# ESP32-S31 register map
Vendor: ESPRESSIF SYSTEMS (SHANGHAI) CO., LTD.; Series: ESP32 S-Series; File version: 1
CPU: RV32IMAFC r0p0, little endian, no MPU, FPU, 0 interrupt priority bits
Address unit: 32 bits
Registers are 32-bit, read-write, reset 0x0 unless marked. A register's access mark holds for its fields unless they carry their own. Offsets are from the block's base; [hi:lo] are bit positions; {n}, {i} and the like mark numbered series.

## HP_SYS — High-Power System
Base 0x20586000
0x00 VER_DATE reset 0x20250402
  [31:0] HP_REG_VER_DATE
0x04 HP_CLK_EN
  [0] HP_REG_CLK_EN
{0x10+4i} HP_CPU_INT_FROM_CPU_{i} (i=0..3)
  [0] HP_CPU_INT_FROM_CPU_{i} — set 1 will triger a interrupt
0x28 HP_MODEM_DIAG_EN
  [31:0] HP_REG_MODEM_DIAG_EN — set reg_modem_diag_en[15:0] will let hp_probe_out[15:0] used as modem_diag[15:0], set reg_modem_diag_en[31:16] will let lcd_data_out[15:0] used as modem_diag[31:16]
0x3C HP_TCM_RAM_PWR_CTRL0
  [0] HP_REG_HP_TCM_CLK_FORCE_ON — hp_tcm clk gatig force on
0x40 HP_ROM_PWR_CTRL0
  [0] HP_REG_HP_ROM_CLK_FORCE_ON — hp_rom clk gating force on
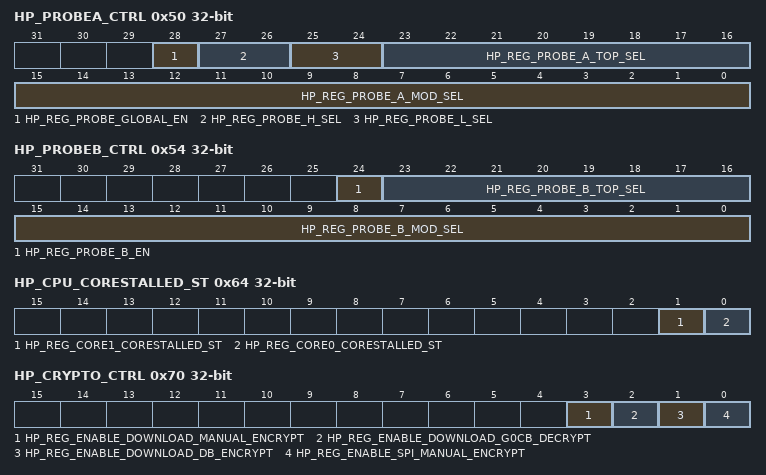
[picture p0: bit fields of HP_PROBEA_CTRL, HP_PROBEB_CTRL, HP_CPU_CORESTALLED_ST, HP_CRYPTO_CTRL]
0x50 HP_PROBEA_CTRL
  [28] HP_REG_PROBE_GLOBAL_EN — Set this bit to enable global debug probe in hp system.
  [27:26] HP_REG_PROBE_H_SEL — Tihs field is used to selec probe_out[31:16]
  [25:24] HP_REG_PROBE_L_SEL — Tihs field is used to selec probe_out[31:16]
  [23:16] HP_REG_PROBE_A_TOP_SEL — Tihs field is used to selec module's probe_out[31:0] as probe out in a mode
  [15:0] HP_REG_PROBE_A_MOD_SEL — Tihs field is used to selec probe_group from probe_group0 to probe_group15 for module's probe_out[31:0] in a mode
0x54 HP_PROBEB_CTRL
  [24] HP_REG_PROBE_B_EN — Set this bit to enable b mode for debug probe. 1: b mode, 0: a mode.
  [23:16] HP_REG_PROBE_B_TOP_SEL — Tihs field is used to select module's probe_out[31:0] as probe_out in b mode
  [15:0] HP_REG_PROBE_B_MOD_SEL — Tihs field is used to selec probe_group from probe_group0 to probe_group15 for module's probe_out[31:0] in b mode.
0x5C HP_PROBE_OUT ro
  [31:0] HP_REG_PROBE_TOP_OUT
0x64 HP_CPU_CORESTALLED_ST ro
  [1] HP_REG_CORE1_CORESTALLED_ST — hp core1 corestalled status
  [0] HP_REG_CORE0_CORESTALLED_ST — hp core0 corestalled status
0x70 HP_CRYPTO_CTRL
  [3] HP_REG_ENABLE_DOWNLOAD_MANUAL_ENCRYPT, [2] HP_REG_ENABLE_DOWNLOAD_G0CB_DECRYPT, [1] HP_REG_ENABLE_DOWNLOAD_DB_ENCRYPT, [0] HP_REG_ENABLE_SPI_MANUAL_ENCRYPT
0x7C HP_IOMUX_FPGA_DEBUG reset 0x1
  [0] HP_REG_FPGA_DEBUG — iomux fpga debug
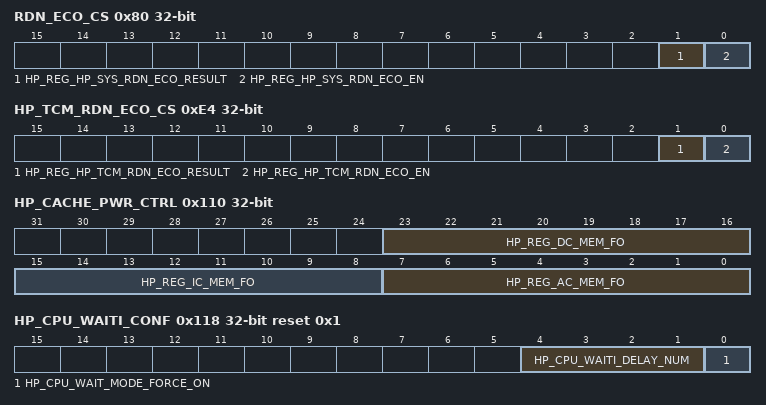
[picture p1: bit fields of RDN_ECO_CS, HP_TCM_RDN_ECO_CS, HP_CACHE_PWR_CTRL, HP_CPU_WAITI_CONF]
0x80 RDN_ECO_CS access per field
  [1] HP_REG_HP_SYS_RDN_ECO_RESULT ro, [0] HP_REG_HP_SYS_RDN_ECO_EN rw
0xE4 HP_TCM_RDN_ECO_CS access per field
  [1] HP_REG_HP_TCM_RDN_ECO_RESULT ro, [0] HP_REG_HP_TCM_RDN_ECO_EN rw
0xE8 HP_TCM_RDN_ECO_LOW
  [31:0] HP_REG_HP_TCM_RDN_ECO_LOW
0xEC HP_TCM_RDN_ECO_HIGH reset 0xFFFFFFFF
  [31:0] HP_REG_HP_TCM_RDN_ECO_HIGH
0x110 HP_CACHE_PWR_CTRL
  [23:16] HP_REG_DC_MEM_FO — need_des
  [15:8] HP_REG_IC_MEM_FO — need_des
  [7:0] HP_REG_AC_MEM_FO — need_des
0x114 HP_TCM_DATA_DUMP_CTRL — need_des
  [31:0] HP_TCM_DATA_DUMP_EN — hp tcm_data dump switch
0x118 HP_CPU_WAITI_CONF reset 0x1 — CPU_WAITI configuration register
  [4:1] HP_CPU_WAITI_DELAY_NUM — This field used to set delay cycle when cpu enter waiti mode, after delay waiti_clk will close
  [0] HP_CPU_WAIT_MODE_FORCE_ON — Set 1 to force cpu_waiti_clk enable.
0x11C CORE_DEBUG_RUNSTALL_CONF — Core Debug runstall configure register
  [0] CORE_DEBUG_RUNSTALL_ENABLE — Set this field to 1 to enable debug runstall feature between HP-core and LP-core.
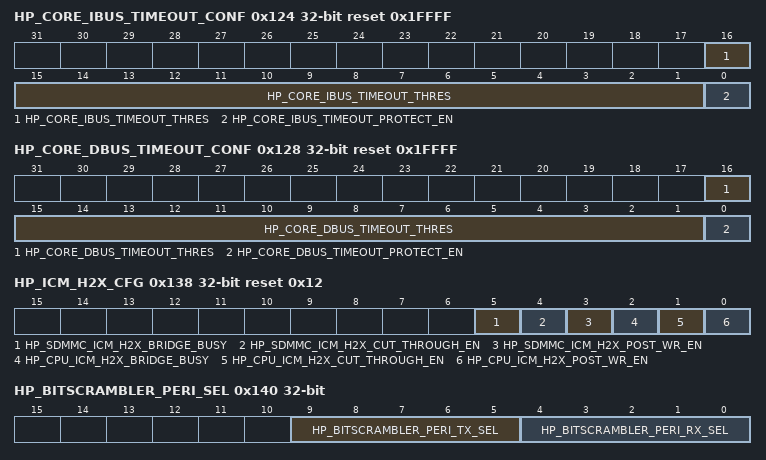
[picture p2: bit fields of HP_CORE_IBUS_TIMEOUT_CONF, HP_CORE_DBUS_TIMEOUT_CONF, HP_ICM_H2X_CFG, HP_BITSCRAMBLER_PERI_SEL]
0x124 HP_CORE_IBUS_TIMEOUT_CONF reset 0x1FFFF — need_des
  [16:1] HP_CORE_IBUS_TIMEOUT_THRES — This field used to set hp core0&1 ibus timeout threshold
  [0] HP_CORE_IBUS_TIMEOUT_PROTECT_EN — set this field to 1 to enable hp core0&1 ibus timeout handle
0x128 HP_CORE_DBUS_TIMEOUT_CONF reset 0x1FFFF — need_des
  [16:1] HP_CORE_DBUS_TIMEOUT_THRES — This field used to set hp core0&1 dbus timeout threshold
  [0] HP_CORE_DBUS_TIMEOUT_PROTECT_EN — set this field to 1 to enable hp core0&1 dbus timeout handle
0x138 HP_ICM_H2X_CFG access per field reset 0x12 — need_des
  [5] HP_SDMMC_ICM_H2X_BRIDGE_BUSY ro — need_des
  [4] HP_SDMMC_ICM_H2X_CUT_THROUGH_EN rw — need_des
  [3] HP_SDMMC_ICM_H2X_POST_WR_EN rw — need_des
  [2] HP_CPU_ICM_H2X_BRIDGE_BUSY ro — need_des
  [1] HP_CPU_ICM_H2X_CUT_THROUGH_EN rw — need_des
  [0] HP_CPU_ICM_H2X_POST_WR_EN rw — need_des
0x140 HP_BITSCRAMBLER_PERI_SEL — Bitscrambler Peri Sel
  [9:5] HP_BITSCRAMBLER_PERI_TX_SEL — Set this field to sel peri with DMA TX interface to connec with bitscrambler: lcd_cam: 5'h1, gpspi2: 5'h2: gpspi3: 5'h3, parl_io:5'h4, aes: 5'h5, sha: 5'h6, adc: 5'h7, i2s0_ch0: 5'h8, i2s0_ch1: 5'h9, i2s0_ch2: 5'ha, i2s0_ch3: 5'hb, i2s1_ch0: 5'hc, i2s1_ch1: 5'hd, i2s1_ch2: 5'he, i2s1_ch3: 5'hf, uhci0: 5'h10, RMT: 5'h11, none: else.
  [4:0] HP_BITSCRAMBLER_PERI_RX_SEL — Set this field to sel peri with DMA RX interface to connec with bitscrambler: lcd_cam: 5'h1, gpspi2: 5'h2: gpspi3: 5'h3, parl_io:5'h4, aes: 5'h5, sha: 5'h6, adc: 5'h7, i2s0_ch0: 5'h8, i2s0_ch1: 5'h9, i2s0_ch2: 5'ha, i2s0_ch3: 5'hb, i2s1_ch0: 5'hc, i2s1_ch1: 5'hd, i2s1_ch2: 5'he, i2s1_ch3: 5'hf, uhci0: 5'h10, RMT: 5'h11, none: else.
0x148 GDMA_CTRL
  [1:0] DEBUG_CH_NUM
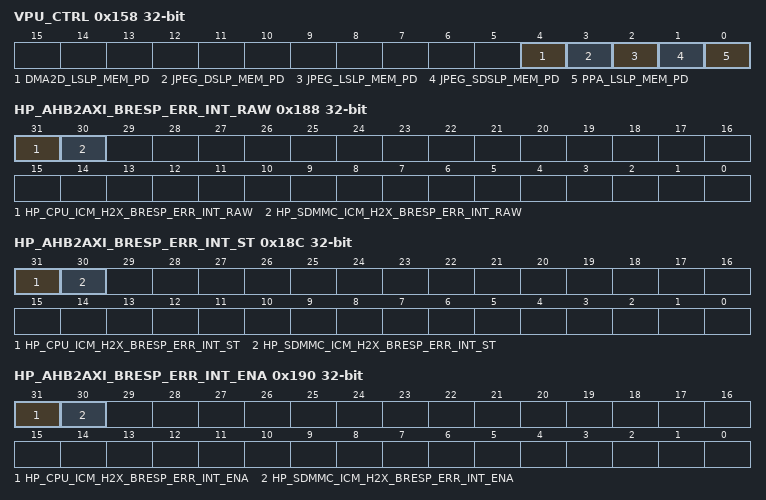
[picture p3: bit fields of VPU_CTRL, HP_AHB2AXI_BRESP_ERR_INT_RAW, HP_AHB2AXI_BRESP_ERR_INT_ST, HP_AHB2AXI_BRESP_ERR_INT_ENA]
0x158 VPU_CTRL
  [4] DMA2D_LSLP_MEM_PD, [3] JPEG_DSLP_MEM_PD, [2] JPEG_LSLP_MEM_PD, [1] JPEG_SDSLP_MEM_PD, [0] PPA_LSLP_MEM_PD
0x170 HP_DESIGN_FOR_VERIFICATION0 — need_des
  [31:0] HP_DFV0 — register for DV
0x174 HP_DESIGN_FOR_VERIFICATION1 — need_des
  [31:0] HP_DFV1 — register for DV
0x188 HP_AHB2AXI_BRESP_ERR_INT_RAW
  [31] HP_CPU_ICM_H2X_BRESP_ERR_INT_RAW — the raw interrupt status of bresp error, triggered when if bresp err occurs in post write mode in ahb2axi.
  [30] HP_SDMMC_ICM_H2X_BRESP_ERR_INT_RAW — the raw interrupt status of bresp error, triggered when if bresp err occurs in post write mode in ahb2axi.
0x18C HP_AHB2AXI_BRESP_ERR_INT_ST ro — need_des
  [31] HP_CPU_ICM_H2X_BRESP_ERR_INT_ST — the masked interrupt status of cpu_icm_h2x_bresp_err
  [30] HP_SDMMC_ICM_H2X_BRESP_ERR_INT_ST — the masked interrupt status of sdmmc_icm_h2x_bresp_err
0x190 HP_AHB2AXI_BRESP_ERR_INT_ENA — need_des
  [31] HP_CPU_ICM_H2X_BRESP_ERR_INT_ENA — Write 1 to enable cpu_icm_h2x_bresp_err int
  [30] HP_SDMMC_ICM_H2X_BRESP_ERR_INT_ENA — Write 1 to enable sdmmc_icm_h2x_bresp_err int
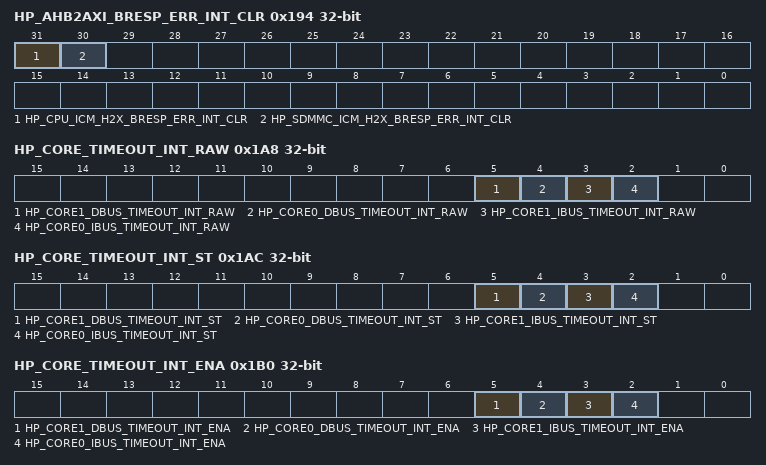
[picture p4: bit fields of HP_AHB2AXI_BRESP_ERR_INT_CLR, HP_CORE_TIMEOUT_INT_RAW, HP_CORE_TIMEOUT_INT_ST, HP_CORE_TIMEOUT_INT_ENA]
0x194 HP_AHB2AXI_BRESP_ERR_INT_CLR wo — need_des
  [31] HP_CPU_ICM_H2X_BRESP_ERR_INT_CLR — Write 1 to clear cpu_icm_h2x_bresp_err int
  [30] HP_SDMMC_ICM_H2X_BRESP_ERR_INT_CLR — Write 1 to clear sdmmc_icm_h2x_bresp_err int
0x1A0 HP_CORE_DMACTIVE_LPCORE ro — need_des
  [0] HP_CORE_DMACTIVE_LPCORE — hp core dmactive_lpcore value
0x1A4 HP_CORE_ERR_RESP_DIS — need_des
  [2:0] HP_CORE_ERR_RESP_DIS — Set bit0 to disable ibus err resp. Set bit1 to disable dbus err resp. Set bit 2 to disable ahb err resp.
0x1A8 HP_CORE_TIMEOUT_INT_RAW — Hp core bus timeout interrupt raw register
  [5] HP_CORE1_DBUS_TIMEOUT_INT_RAW — the raw interrupt status of hp core1 dbus timeout
  [4] HP_CORE0_DBUS_TIMEOUT_INT_RAW — the raw interrupt status of hp core0 dbus timeout
  [3] HP_CORE1_IBUS_TIMEOUT_INT_RAW — the raw interrupt status of hp core1 ibus timeout
  [2] HP_CORE0_IBUS_TIMEOUT_INT_RAW — the raw interrupt status of hp core0 ibus timeout
0x1AC HP_CORE_TIMEOUT_INT_ST ro — masked interrupt register
  [5] HP_CORE1_DBUS_TIMEOUT_INT_ST — the masked interrupt status of hp core1 dbus timeout
  [4] HP_CORE0_DBUS_TIMEOUT_INT_ST — the masked interrupt status of hp core0 dbus timeout
  [3] HP_CORE1_IBUS_TIMEOUT_INT_ST — the masked interrupt status of hp core1 ibus timeout
  [2] HP_CORE0_IBUS_TIMEOUT_INT_ST — the masked interrupt status of hp core0 ibus timeout
0x1B0 HP_CORE_TIMEOUT_INT_ENA — masked interrupt register
  [5] HP_CORE1_DBUS_TIMEOUT_INT_ENA — Write 1 to enable hp_core1_dbus_timeout int
  [4] HP_CORE0_DBUS_TIMEOUT_INT_ENA — Write 1 to enable hp_core0_dbus_timeout int
  [3] HP_CORE1_IBUS_TIMEOUT_INT_ENA — Write 1 to enable hp_core1_ibus_timeout int
  [2] HP_CORE0_IBUS_TIMEOUT_INT_ENA — Write 1 to enable hp_core0_ibus_timeout int
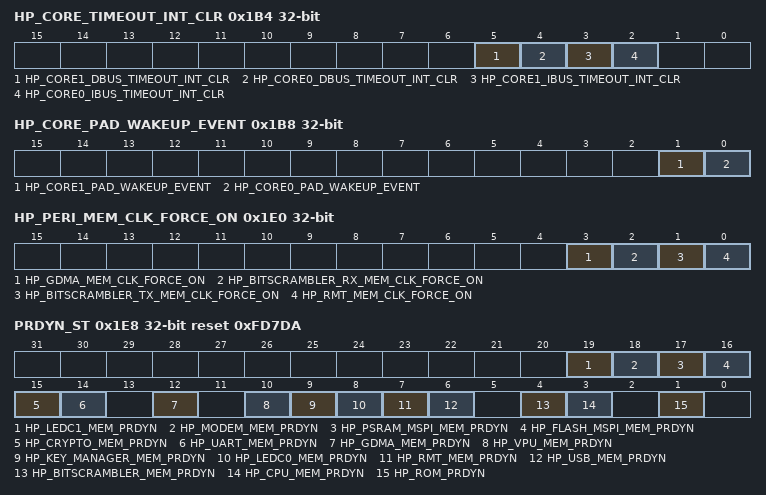
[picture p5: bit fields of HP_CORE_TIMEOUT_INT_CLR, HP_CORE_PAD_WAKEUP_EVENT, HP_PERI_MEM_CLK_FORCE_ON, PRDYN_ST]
0x1B4 HP_CORE_TIMEOUT_INT_CLR wo — interrupt clear register
  [5] HP_CORE1_DBUS_TIMEOUT_INT_CLR — Write 1 to clear hp_core1_dbus_timeout int
  [4] HP_CORE0_DBUS_TIMEOUT_INT_CLR — Write 1 to clear hp_core0_dbus_timeout int
  [3] HP_CORE1_IBUS_TIMEOUT_INT_CLR — Write 1 to clear hp_core1_ibus_timeout int
  [2] HP_CORE0_IBUS_TIMEOUT_INT_CLR — Write 1 to clear hp_core0_ibus_timeout int
0x1B8 HP_CORE_PAD_WAKEUP_EVENT — pad wakeup event register
  [1] HP_CORE1_PAD_WAKEUP_EVENT — wakeup core1 register
  [0] HP_CORE0_PAD_WAKEUP_EVENT — wakeup core0 register
0x1C0 HP_TWAI0_TIMESTAMP_L reset 0xFFFFFFFF — twai0 timestamp low bit reg
  [31:0] HP_TWAI0_TIMESTAMP_I — This field used to set lower 32bits of timestamp hp twai0
0x1C4 HP_TWAI0_TIMESTAMP_H reset 0xFFFFFFFF — twai0 timestamp high bit reg
  [31:0] HP_TWAI0_TIMESTAMP_H — This field used to set upper 32bits of timestamp hp twai0
0x1C8 HP_TWAI1_TIMESTAMP_L reset 0xFFFFFFFF — twai1 timestamp low bit reg
  [31:0] HP_TWAI1_TIMESTAMP_I — This field used to set lower 32bits of timestamp hp twai1
0x1CC HP_TWAI1_TIMESTAMP_H reset 0xFFFFFFFF — twai1 timestamp high bit reg
  [31:0] HP_TWAI1_TIMESTAMP_H — This field used to set upper 32bits of timestamp hp twai1
0x1D8 HP_RNG_CFG — rng cfg register
  [23:16] HP_RNG_CHAIN_CLK_DIV_NUM — chain clk div num to pad for debug
0x1E0 HP_PERI_MEM_CLK_FORCE_ON — hp peri mem clk force on regpster
  [3] HP_GDMA_MEM_CLK_FORCE_ON — Set this bit to force on mem clk in gdma
  [2] HP_BITSCRAMBLER_RX_MEM_CLK_FORCE_ON — Set this bit to force on rx mem clk in bitscrambler
  [1] HP_BITSCRAMBLER_TX_MEM_CLK_FORCE_ON — Set this bit to force on tx mem clk in bitscrambler
  [0] HP_RMT_MEM_CLK_FORCE_ON — Set this bit to force on mem clk in rmt
0x1E8 PRDYN_ST ro reset 0xFD7DA — hp system prdyn status register
  [19] HP_LEDC1_MEM_PRDYN — record memory power status
  [18] HP_MODEM_MEM_PRDYN — record memory power status
  [17] HP_PSRAM_MSPI_MEM_PRDYN — record memory power status
  [16] HP_FLASH_MSPI_MEM_PRDYN — record memory power status
  [15] HP_CRYPTO_MEM_PRDYN — record memory power status
  [14] HP_UART_MEM_PRDYN — record memory power status
  [12] HP_GDMA_MEM_PRDYN — record memory power status
  [10] HP_VPU_MEM_PRDYN — record memory power status
  [9] HP_KEY_MANAGER_MEM_PRDYN — record memory power status
  [8] HP_LEDC0_MEM_PRDYN — record memory power status
  [7] HP_RMT_MEM_PRDYN — record memory power status
  [6] HP_USB_MEM_PRDYN — record memory power status
  [4] HP_BITSCRAMBLER_MEM_PRDYN — record memory power status
  [3] HP_CPU_MEM_PRDYN — record memory power status
  [1] HP_ROM_PRDYN — record memory power status
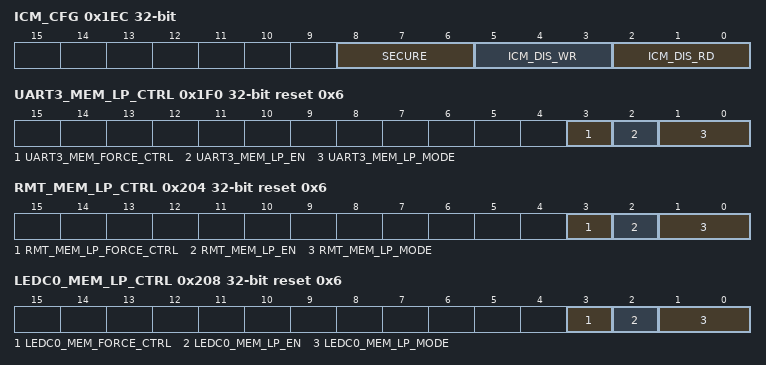
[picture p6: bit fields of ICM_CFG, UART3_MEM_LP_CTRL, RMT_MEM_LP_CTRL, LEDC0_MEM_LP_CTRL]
0x1EC ICM_CFG — hp system axi icm ctrl register
  [8:6] SECURE — axi_matrix slave ,0: non-secure, 1: secure , total 3 slave.
  [5:3] ICM_DIS_WR — 0:mean master can acess slave , 1:mean master can not wr slave ,will returen decerro on axi bus
  [2:0] ICM_DIS_RD — 0:mean master can acess slave , 1:mean master can not rd slave ,will returen decerro on axi bus
0x1F0 UART3_MEM_LP_CTRL reset 0x6 — uart memory power control register
  [3] UART3_MEM_FORCE_CTRL — Set this bit to force software control uart3 memory, disbale hardware control.
  [2] UART3_MEM_LP_EN — Set this bit to power down uart3 memory.
  [1:0] UART3_MEM_LP_MODE — Configures uart3 memory low power mode in low power stage.\\ 0(default): deep sleep\\ 1: light sleep\\ 2: shut down\\ 3: disable low power stage\\
0x204 RMT_MEM_LP_CTRL reset 0x6 — rmt memory power control register
  [3] RMT_MEM_LP_FORCE_CTRL — Set this bit to force software control rmt memory, disbale hardware control.
  [2] RMT_MEM_LP_EN — Set this bit to power down rmt memory.
  [1:0] RMT_MEM_LP_MODE — Configures rmt memory low power mode in low power stage.\\ 0(default): deep sleep\\ 1: light sleep\\ 2: shut down\\ 3: disable low power stage\\
0x208 LEDC0_MEM_LP_CTRL reset 0x6 — ledc0 memory power control register
  [3] LEDC0_MEM_FORCE_CTRL — Set this bit to force software control ledc0 memory, disbale hardware control.
  [2] LEDC0_MEM_LP_EN — Set this bit to power down ledc0 memory.
  [1:0] LEDC0_MEM_LP_MODE — Configures ledc0 memory low power mode in low power stage.\\ 0(default): deep sleep\\ 1: light sleep\\ 2: shut down\\ 3: disable low power stage\\
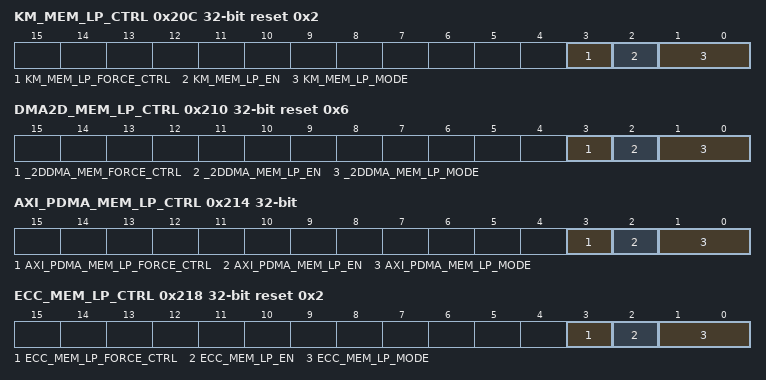
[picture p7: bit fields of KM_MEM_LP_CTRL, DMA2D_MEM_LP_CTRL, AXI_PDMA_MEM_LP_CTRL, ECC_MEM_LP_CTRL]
0x20C KM_MEM_LP_CTRL reset 0x2 — key manager memory power control register
  [3] KM_MEM_LP_FORCE_CTRL — Set this bit to force software control km memory, disbale hardware control.
  [2] KM_MEM_LP_EN — Set this bit to power down km memory.
  [1:0] KM_MEM_LP_MODE — Configures km memory low power mode in low power stage.\\ 0(default): deep sleep\\ 1: light sleep\\ 2: shut down\\ 3: disable low power stage\\
0x210 DMA2D_MEM_LP_CTRL reset 0x6 — vpu memory power control register
  [3] _2DDMA_MEM_FORCE_CTRL — Set this bit to force software control 2ddma memory, disbale hardware control.
  [2] _2DDMA_MEM_LP_EN — Set this bit to power down 2ddma memory.
  [1:0] _2DDMA_MEM_LP_MODE — Configures 2ddma memory low power mode in low power stage.\\ 0(default): deep sleep\\ 1: light sleep\\ 2: shut down\\ 3: disable low power stage\\
0x214 AXI_PDMA_MEM_LP_CTRL — vpu memory power control register
  [3] AXI_PDMA_MEM_LP_FORCE_CTRL — Set this bit to force software control axi_pdma memory, disbale hardware control.
  [2] AXI_PDMA_MEM_LP_EN — Set this bit to power down axi_pdma memory.
  [1:0] AXI_PDMA_MEM_LP_MODE — Configures axi_pdma memory low power mode in low power stage.\\ 0(default): deep sleep\\ 1: light sleep\\ 2: shut down\\ 3: disable low power stage\\
0x218 ECC_MEM_LP_CTRL reset 0x2 — HP CORE0 & HP CORE1 memory power control register
  [3] ECC_MEM_LP_FORCE_CTRL — Set this bit to force software control ecc memory, disbale hardware control.
  [2] ECC_MEM_LP_EN — Set this bit to power down ecc memory.
  [1:0] ECC_MEM_LP_MODE — Configures ecc memory low power mode in low power stage.\\ 0: deep sleep\\ 1: light sleep\\ 2(default): shut down\\ 3: disable low power stage\\
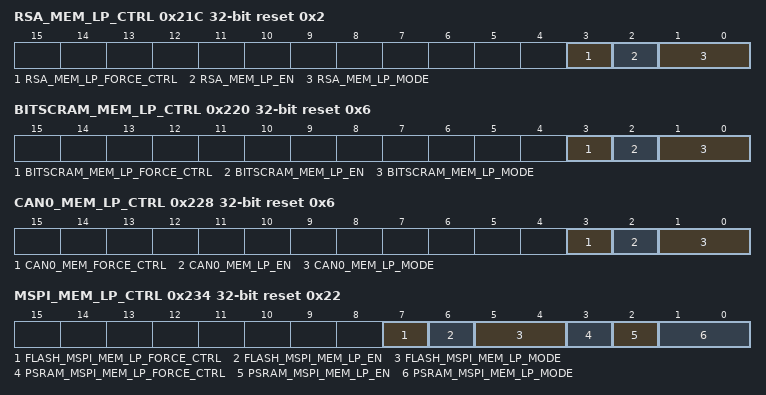
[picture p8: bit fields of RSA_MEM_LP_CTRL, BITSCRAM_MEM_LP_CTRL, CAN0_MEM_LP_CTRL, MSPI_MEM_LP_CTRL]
0x21C RSA_MEM_LP_CTRL reset 0x2 — HP CORE0 & HP CORE1 memory power control register
  [3] RSA_MEM_LP_FORCE_CTRL — Set this bit to force software control rsa memory, disbale hardware control.
  [2] RSA_MEM_LP_EN — Set this bit to power down rsa memory.
  [1:0] RSA_MEM_LP_MODE — Configures rsa memory low power mode in low power stage.\\ 0: deep sleep\\ 1: light sleep\\ 2(default): shut down\\ 3: disable low power stage\\
0x220 BITSCRAM_MEM_LP_CTRL reset 0x6 — HP CORE0 & HP CORE1 memory power control register
  [3] BITSCRAM_MEM_LP_FORCE_CTRL — Set this bit to force software control bitscram memory, disbale hardware control.
  [2] BITSCRAM_MEM_LP_EN — Set this bit to power down bitscram memory.
  [1:0] BITSCRAM_MEM_LP_MODE — Configures bitscram memory low power mode in low power stage.\\ 0: deep sleep\\ 1: light sleep\\ 2(default): shut down\\ 3: disable low power stage\\
0x228 CAN0_MEM_LP_CTRL reset 0x6 — HP CORE0 & HP CORE1 memory power control register
  [3] CAN0_MEM_FORCE_CTRL — Set this bit to force software control can0 memory, disbale hardware control.
  [2] CAN0_MEM_LP_EN — Set this bit to power down can0 memory.
  [1:0] CAN0_MEM_LP_MODE — Configures can0 memory low power mode in low power stage.\\ 0(default): deep sleep\\ 1: light sleep\\ 2: shut down\\ 3: disable low power stage\\
0x234 MSPI_MEM_LP_CTRL reset 0x22 — HP CORE0 & HP CORE1 memory power control register
  [7] FLASH_MSPI_MEM_LP_FORCE_CTRL — Set this bit to force software control flash_mspi memory, disbale hardware control.
  [6] FLASH_MSPI_MEM_LP_EN — Set this bit to power down flash_mspi memory.
  [5:4] FLASH_MSPI_MEM_LP_MODE — Configures flash_mspi memory low power mode in low power stage.\\ 0: deep sleep\\ 1: light sleep\\ 2(default): shut down\\ 3: disable low power stage\\
  [3] PSRAM_MSPI_MEM_LP_FORCE_CTRL — Set this bit to force software control psram_mspi memory, disbale hardware control.
  [2] PSRAM_MSPI_MEM_LP_EN — Set this bit to power down psram_mspi memory.
  [1:0] PSRAM_MSPI_MEM_LP_MODE — Configures psram_mspi memory low power mode in low power stage.\\ 0: deep sleep\\ 1: light sleep\\ 2(default): shut down\\ 3: disable low power stage\\
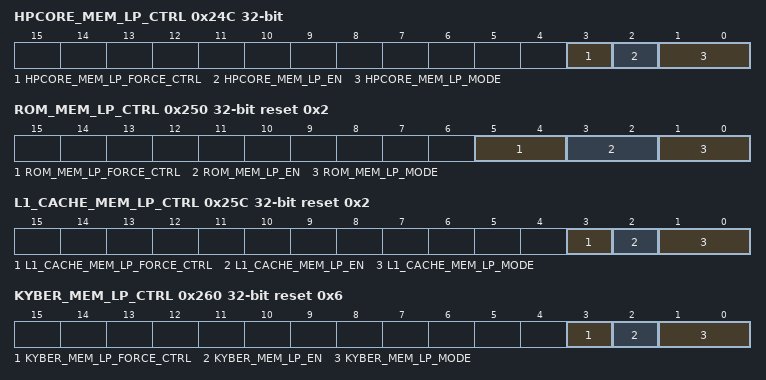
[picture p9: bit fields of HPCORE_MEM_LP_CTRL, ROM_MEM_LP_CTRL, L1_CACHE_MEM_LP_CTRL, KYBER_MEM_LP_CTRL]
0x24C HPCORE_MEM_LP_CTRL — HP CORE0 & HP CORE1 memory power control register
  [3] HPCORE_MEM_LP_FORCE_CTRL — Set this bit to force software control hpcore memory, disbale hardware control.
  [2] HPCORE_MEM_LP_EN — Set this bit to power down hpcore memory.
  [1:0] HPCORE_MEM_LP_MODE — Configures hpcore memory low power mode in low power stage.\\ 0: deep sleep\\ 1: light sleep\\ 2(default): shut down\\ 3: disable low power stage\\
0x250 ROM_MEM_LP_CTRL reset 0x2 — rom power control register
  [5:4] ROM_MEM_LP_FORCE_CTRL — Set this bit to force software control rom, disbale hardware control.
  [3:2] ROM_MEM_LP_EN — Set this bit to power down rom.
  [1:0] ROM_MEM_LP_MODE — Configures rom low power mode in low power stage.\\ 0(default): deep sleep\\ 1: light sleep\\ 2: shut down\\ 3: disable low power stage\\
0x25C L1_CACHE_MEM_LP_CTRL reset 0x2 — HP CORE0 & HP CORE1 memory power control register
  [3] L1_CACHE_MEM_LP_FORCE_CTRL — Set this bit to force software control l1_cache memory, disbale hardware control.
  [2] L1_CACHE_MEM_LP_EN — Set this bit to power down l1_cache memory.
  [1:0] L1_CACHE_MEM_LP_MODE — Configures l1_cache memory low power mode in low power stage.\\ 0: deep sleep\\ 1: light sleep\\ 2(default): shut down\\ 3: disable low power stage\\
0x260 KYBER_MEM_LP_CTRL reset 0x6 — HP CORE0 & HP CORE1 memory power control register
  [3] KYBER_MEM_LP_FORCE_CTRL — Set this bit to force software control kyber memory, disbale hardware control.
  [2] KYBER_MEM_LP_EN — Set this bit to power down kyber memory.
  [1:0] KYBER_MEM_LP_MODE — Configures kyber memory low power mode in low power stage.\\ 0: deep sleep\\ 1: light sleep\\ 2(default): shut down\\ 3: disable low power stage\\
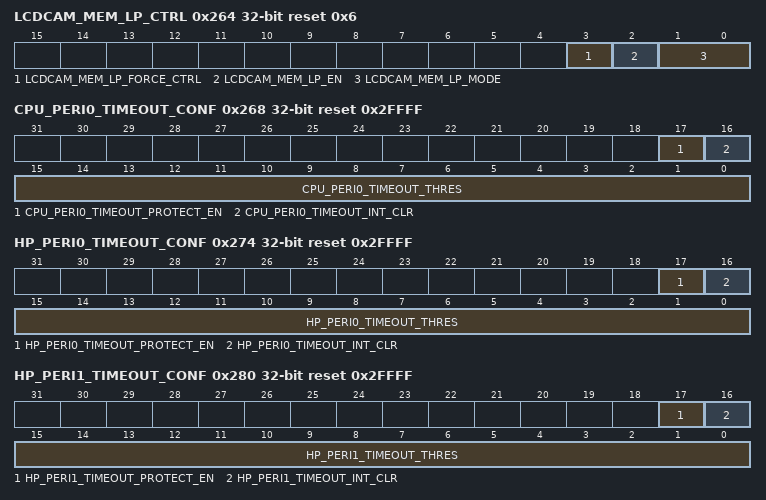
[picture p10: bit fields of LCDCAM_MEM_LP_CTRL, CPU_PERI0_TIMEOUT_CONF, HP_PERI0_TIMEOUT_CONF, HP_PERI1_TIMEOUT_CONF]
0x264 LCDCAM_MEM_LP_CTRL reset 0x6 — HP CORE0 & HP CORE1 memory power control register
  [3] LCDCAM_MEM_LP_FORCE_CTRL — Set this bit to force software control lcdcam memory, disbale hardware control.
  [2] LCDCAM_MEM_LP_EN — Set this bit to power down lcdcam memory.
  [1:0] LCDCAM_MEM_LP_MODE — Configures lcdcam memory low power mode in low power stage.\\ 0: deep sleep\\ 1: light sleep\\ 2(default): shut down\\ 3: disable low power stage\\
0x268 CPU_PERI0_TIMEOUT_CONF access per field reset 0x2FFFF — CPU_PERI0_TIMEOUT configuration register
  [17] CPU_PERI0_TIMEOUT_PROTECT_EN rw — Configures whether or not to enable timeout protection for accessing CPU peripheral0 registers.\\ 0: Disable\\ 1: Enable\\
  [16] CPU_PERI0_TIMEOUT_INT_CLR wo — Write 1 to clear timeout interrupt.
  [15:0] CPU_PERI0_TIMEOUT_THRES rw — Configures the timeout threshold for bus access for accessing CPU peripheral0 register in the number of clock cycles of the clock domain.
0x26C CPU_PERI0_TIMEOUT_ADDR ro
  [31:0] CPU_PERI0_TIMEOUT_ADDR — Represents the address information of abnormal access.
0x270 CPU_PERI0_TIMEOUT_UID ro
  [7:0] CPU_PERI0_TIMEOUT_UID — Represents the master id[5:0] and master permission[6:5] when trigger timeout. This register will be cleared after the interrupt is cleared.
0x274 HP_PERI0_TIMEOUT_CONF access per field reset 0x2FFFF — HP_PERI0_TIMEOUT configuration register
  [17] HP_PERI0_TIMEOUT_PROTECT_EN rw — Configures whether or not to enable timeout protection for accessing CPU peripheral registers.\\ 0: Disable\\ 1: Enable\\
  [16] HP_PERI0_TIMEOUT_INT_CLR wo — Write 1 to clear timeout interrupt.
  [15:0] HP_PERI0_TIMEOUT_THRES rw — Configures the timeout threshold for bus access for accessing CPU peripheral register in the number of clock cycles of the clock domain.
0x278 HP_PERI0_TIMEOUT_ADDR ro
  [31:0] HP_PERI0_TIMEOUT_ADDR — Represents the address information of abnormal access.
0x27C HP_PERI0_TIMEOUT_UID ro
  [7:0] HP_PERI0_TIMEOUT_UID — Represents the master id[5:0] and master permission[6:5] when trigger timeout. This register will be cleared after the interrupt is cleared.
0x280 HP_PERI1_TIMEOUT_CONF access per field reset 0x2FFFF — HP_PERI1_TIMEOUT configuration register
  [17] HP_PERI1_TIMEOUT_PROTECT_EN rw — Configures whether or not to enable timeout protection for accessing CPU peripheral registers.\\ 0: Disable\\ 1: Enable\\
  [16] HP_PERI1_TIMEOUT_INT_CLR wo — Write 1 to clear timeout interrupt.
  [15:0] HP_PERI1_TIMEOUT_THRES rw — Configures the timeout threshold for bus access for accessing CPU peripheral register in the number of clock cycles of the clock domain.
0x284 HP_PERI1_TIMEOUT_ADDR ro
  [31:0] HP_PERI1_TIMEOUT_ADDR — Represents the address information of abnormal access.
0x288 HP_PERI1_TIMEOUT_UID ro
  [7:0] HP_PERI1_TIMEOUT_UID — Represents the master id[5:0] and master permission[6:5] when trigger timeout. This register will be cleared after the interrupt is cleared.
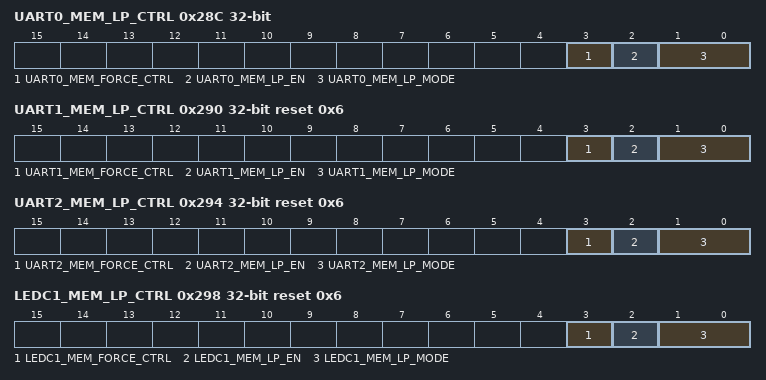
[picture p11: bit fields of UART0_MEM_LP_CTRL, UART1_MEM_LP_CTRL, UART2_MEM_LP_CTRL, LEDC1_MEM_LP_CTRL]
0x28C UART0_MEM_LP_CTRL — uart memory power control register
  [3] UART0_MEM_FORCE_CTRL — Set this bit to force software control uart0 memory, disbale hardware control.
  [2] UART0_MEM_LP_EN — Set this bit to power down uart0 memory.
  [1:0] UART0_MEM_LP_MODE — Configures uart0 memory low power mode in low power stage.\\ 0(default): deep sleep\\ 1: light sleep\\ 2: shut down\\ 3: disable low power stage\\
0x290 UART1_MEM_LP_CTRL reset 0x6 — uart memory power control register
  [3] UART1_MEM_FORCE_CTRL — Set this bit to force software control uart1 memory, disbale hardware control.
  [2] UART1_MEM_LP_EN — Set this bit to power down uart1 memory.
  [1:0] UART1_MEM_LP_MODE — Configures uart1 memory low power mode in low power stage.\\ 0(default): deep sleep\\ 1: light sleep\\ 2: shut down\\ 3: disable low power stage\\
0x294 UART2_MEM_LP_CTRL reset 0x6 — uart memory power control register
  [3] UART2_MEM_FORCE_CTRL — Set this bit to force software control uart2 memory, disbale hardware control.
  [2] UART2_MEM_LP_EN — Set this bit to power down uart2 memory.
  [1:0] UART2_MEM_LP_MODE — Configures uart2 memory low power mode in low power stage.\\ 0(default): deep sleep\\ 1: light sleep\\ 2: shut down\\ 3: disable low power stage\\
0x298 LEDC1_MEM_LP_CTRL reset 0x6 — ledc1 memory power control register
  [3] LEDC1_MEM_FORCE_CTRL — Set this bit to force software control ledc1 memory, disbale hardware control.
  [2] LEDC1_MEM_LP_EN — Set this bit to power down ledc1 memory.
  [1:0] LEDC1_MEM_LP_MODE — Configures ledc1 memory low power mode in low power stage.\\ 0(default): deep sleep\\ 1: light sleep\\ 2: shut down\\ 3: disable low power stage\\
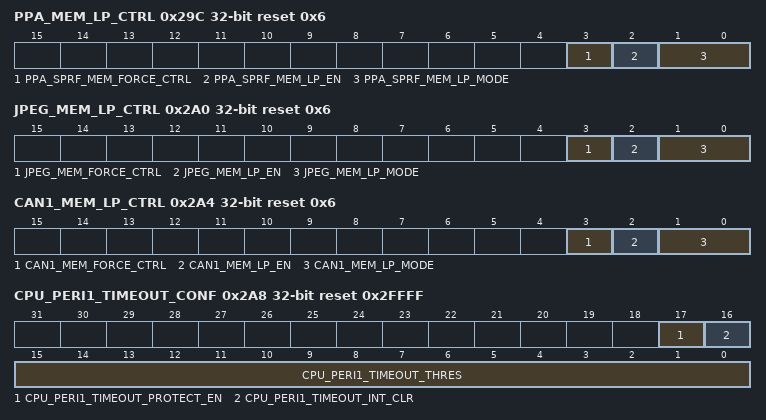
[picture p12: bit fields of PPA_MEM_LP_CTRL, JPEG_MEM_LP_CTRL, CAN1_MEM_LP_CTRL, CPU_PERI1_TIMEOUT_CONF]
0x29C PPA_MEM_LP_CTRL reset 0x6 — vpu memory power control register
  [3] PPA_SPRF_MEM_FORCE_CTRL — Set this bit to force software control ppa_sprf memory, disbale hardware control.
  [2] PPA_SPRF_MEM_LP_EN — Set this bit to power down ppa_sprf memory.
  [1:0] PPA_SPRF_MEM_LP_MODE — Configures ppa_sprf memory low power mode in low power stage.\\ 0(default): deep sleep\\ 1: light sleep\\ 2: shut down\\ 3: disable low power stage\\
0x2A0 JPEG_MEM_LP_CTRL reset 0x6 — vpu memory power control register
  [3] JPEG_MEM_FORCE_CTRL — Set this bit to force software control jpeg memory, disbale hardware control.
  [2] JPEG_MEM_LP_EN — Set this bit to power down jpeg memory.
  [1:0] JPEG_MEM_LP_MODE — Configures jpeg memory low power mode in low power stage.\\ 0(default): deep sleep\\ 1: light sleep\\ 2: shut down\\ 3: disable low power stage\\
0x2A4 CAN1_MEM_LP_CTRL reset 0x6 — HP CORE0 & HP CORE1 memory power control register
  [3] CAN1_MEM_FORCE_CTRL — Set this bit to force software control can1 memory, disbale hardware control.
  [2] CAN1_MEM_LP_EN — Set this bit to power down can1 memory.
  [1:0] CAN1_MEM_LP_MODE — Configures can1 memory low power mode in low power stage.\\ 0(default): deep sleep\\ 1: light sleep\\ 2: shut down\\ 3: disable low power stage\\
0x2A8 CPU_PERI1_TIMEOUT_CONF access per field reset 0x2FFFF — CPU_PERI1_TIMEOUT configuration register
  [17] CPU_PERI1_TIMEOUT_PROTECT_EN rw — Configures whether or not to enable timeout protection for accessing CPU peripheral11 registers.\\ 0: Disable\\ 1: Enable\\
  [16] CPU_PERI1_TIMEOUT_INT_CLR wo — Write 1 to clear timeout interrupt.
  [15:0] CPU_PERI1_TIMEOUT_THRES rw — Configures the timeout threshold for bus access for accessing CPU peripheral register in the number of clock cycles of the clock domain.
0x2AC CPU_PERI1_TIMEOUT_ADDR ro
  [31:0] CPU_PERI1_TIMEOUT_ADDR — Represents the address information of abnormal access.
0x2B0 CPU_PERI1_TIMEOUT_UID ro
  [7:0] CPU_PERI1_TIMEOUT_UID — Represents the master id[5:0] and master permission[6:5] when trigger timeout. This register will be cleared after the interrupt is cleared.
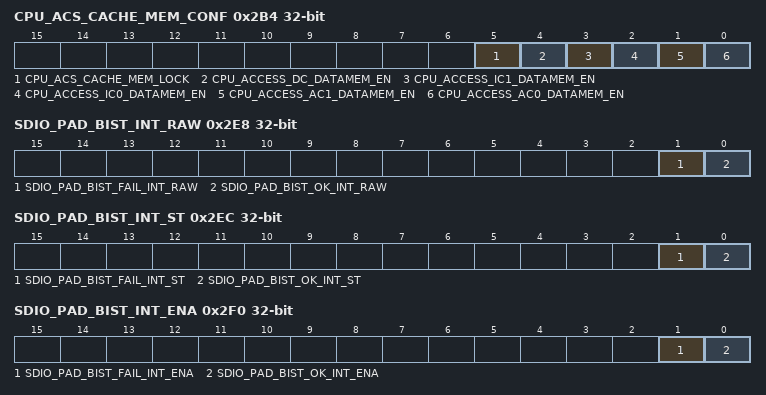
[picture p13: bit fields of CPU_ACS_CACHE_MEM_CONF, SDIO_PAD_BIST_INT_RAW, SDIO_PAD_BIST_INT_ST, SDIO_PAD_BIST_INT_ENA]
0x2B4 CPU_ACS_CACHE_MEM_CONF access per field — CPU access Cache data mem configuration register
  [5] CPU_ACS_CACHE_MEM_LOCK rw — Set 1 to lock cpu acs mem data mem path configuration
  [4] CPU_ACCESS_DC_DATAMEM_EN rw — Set this bit to enable CPU access DCache data mem path
  [3] CPU_ACCESS_IC1_DATAMEM_EN rw — Set this bit to enable CPU access ICache1 data mem path
  [2] CPU_ACCESS_IC0_DATAMEM_EN rw — Set this bit to enable CPU access ICache0 data mem path
  [1] CPU_ACCESS_AC1_DATAMEM_EN ro — Set this bit to enable CPU access ROMCache1 data mem path
  [0] CPU_ACCESS_AC0_DATAMEM_EN ro — Set this bit to enable CPU accessROMCache0 data mem path
0x2E0 TCM_PERFORMACE_CTRL — need_des
  [0] AHB_TO_TCM_MEM_EN_HOLD — Set 1 to keep TCM mem enable hold when mem access is busy.
0x2E4 SDIO_PAD_BIST_CFG wo — sdio pad bist control register
  [0] SDIO_PAD_BIST_START — Write 1 to start sdio pad bist
0x2E8 SDIO_PAD_BIST_INT_RAW — sdio pad bist interupt raw register
  [1] SDIO_PAD_BIST_FAIL_INT_RAW — intr triggered when bist finish and status is bist fail
  [0] SDIO_PAD_BIST_OK_INT_RAW — intr triggered when bist finish and status is bist ok
0x2EC SDIO_PAD_BIST_INT_ST ro — masked interrupt register
  [1] SDIO_PAD_BIST_FAIL_INT_ST — the masked interrupt status of sdio pad bist fail interrupt
  [0] SDIO_PAD_BIST_OK_INT_ST — the masked interrupt status of sdio pad bist ok interrupt
0x2F0 SDIO_PAD_BIST_INT_ENA — interrupt enable register
  [1] SDIO_PAD_BIST_FAIL_INT_ENA — Write 1 to enable sdio pad bist fail interrupt
  [0] SDIO_PAD_BIST_OK_INT_ENA — Write 1 to enable sdio pad bist ok interrupt
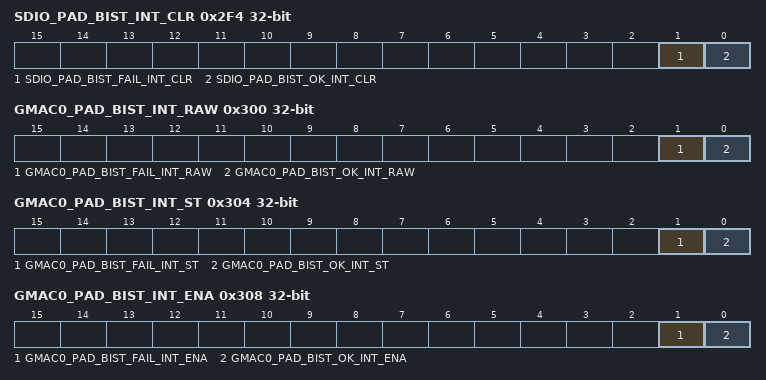
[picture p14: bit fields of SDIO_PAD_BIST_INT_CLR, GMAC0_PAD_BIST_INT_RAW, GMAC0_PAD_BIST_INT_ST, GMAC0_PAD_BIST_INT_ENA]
0x2F4 SDIO_PAD_BIST_INT_CLR wo — interrupt clear register
  [1] SDIO_PAD_BIST_FAIL_INT_CLR — Write 1 to clr sdio pad bist fail interrupt
  [0] SDIO_PAD_BIST_OK_INT_CLR — Write 1 to clr sdio pad bist ok interrupt
0x2F8 SDIO_PAD_BIST_ST ro — sdio pad bist status register
  [5:0] SDIO_PAD_BIST_RCNT — Indicate number of clock cycles received for pad bist debug
0x2FC GMAC0_PAD_BIST_CFG wo — gmac0 pad bist control register
  [0] GMAC0_PAD_BIST_START — Write 1 to start gmac0 pad bist
0x300 GMAC0_PAD_BIST_INT_RAW — gmac0 pad bist interupt raw register
  [1] GMAC0_PAD_BIST_FAIL_INT_RAW — intr triggered when bist finish and status is bist fail
  [0] GMAC0_PAD_BIST_OK_INT_RAW — intr triggered when bist finish and status is bist ok
0x304 GMAC0_PAD_BIST_INT_ST ro — masked interrupt register
  [1] GMAC0_PAD_BIST_FAIL_INT_ST — the masked interrupt status of gmac0 pad bist fail interrupt
  [0] GMAC0_PAD_BIST_OK_INT_ST — the masked interrupt status of gmac0 pad bist ok interrupt
0x308 GMAC0_PAD_BIST_INT_ENA — interrupt enable register
  [1] GMAC0_PAD_BIST_FAIL_INT_ENA — Write 1 to enable gmac0 pad bist fail interrupt
  [0] GMAC0_PAD_BIST_OK_INT_ENA — Write 1 to enable gmac0 pad bist ok interrupt
0x30C GMAC0_PAD_BIST_INT_CLR wo — interrupt clear register
  [1] GMAC0_PAD_BIST_FAIL_INT_CLR — Write 1 to clr gmac0 pad bist fail interrupt
  [0] GMAC0_PAD_BIST_OK_INT_CLR — Write 1 to clr gmac0 pad bist ok interrupt
0x310 GMAC0_PAD_BIST_ST ro — gmac0 pad bist status register
  [5:0] GMAC0_PAD_BIST_RCNT — Indicate number of clock cycles received for pad bist debug
0x314 GMAC1_PAD_BIST_CFG wo — gmac1 pad bist control register
  [0] GMAC1_PAD_BIST_START — Write 1 to start gmac1 pad bist
0x318 GMAC1_PAD_BIST_INT_RAW — gmac1 pad bist interupt raw register
  [1] GMAC1_PAD_BIST_FAIL_INT_RAW — intr triggered when bist finish and status is bist fail
  [0] GMAC1_PAD_BIST_OK_INT_RAW — intr triggered when bist finish and status is bist ok
0x31C GMAC1_PAD_BIST_INT_ST ro — masked interrupt register
  [1] GMAC1_PAD_BIST_FAIL_INT_ST — the masked interrupt status of gmac1 pad bist fail interrupt
  [0] GMAC1_PAD_BIST_OK_INT_ST — the masked interrupt status of gmac1 pad bist ok interrupt
0x320 GMAC1_PAD_BIST_INT_ENA — interrupt enable register
  [1] GMAC1_PAD_BIST_FAIL_INT_ENA — Write 1 to enable gmac1 pad bist fail interrupt
  [0] GMAC1_PAD_BIST_OK_INT_ENA — Write 1 to enable gmac1 pad bist ok interrupt
0x324 GMAC1_PAD_BIST_INT_CLR wo — interrupt clear register
  [1] GMAC1_PAD_BIST_FAIL_INT_CLR — Write 1 to clr gmac1 pad bist fail interrupt
  [0] GMAC1_PAD_BIST_OK_INT_CLR — Write 1 to clr gmac1 pad bist ok interrupt
0x328 GMAC1_PAD_BIST_ST ro — gmac1 pad bist status register
  [5:0] GMAC1_PAD_BIST_RCNT — Indicate number of clock cycles received for pad bist debug
0x32C SDIO_PAD_BIST_CTRL — gmac0 pad bist status register
  [n] SDIO_PAD_BIST_{n}_SEL (n=0..5) — Write 1 to select sdio pad bist signal out, default 0 is normal pad mode
0x330 GMAC0_PAD_BIST_CTRL — gmac0 pad bist status register
  [n] GMAC0_PAD_BIST_{n}_SEL (n=0..5) — Write 1 to select gmac0 pad bist signal out, default 0 is normal pad mode
0x334 GMAC1_PAD_BIST_CTRL — gmac0 pad bist status register
  [n] GMAC1_PAD_BIST_{n}_SEL (n=0..5) — Write 1 to select gmac1 pad bist signal out, default 0 is normal pad mode
0x338 CPU_PWAIT_MODE ro — Indicate status of core0 and core1 pwait
  [1:0] CPU_PWAIT_MODE
